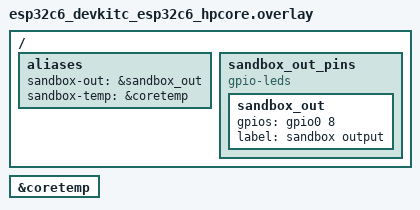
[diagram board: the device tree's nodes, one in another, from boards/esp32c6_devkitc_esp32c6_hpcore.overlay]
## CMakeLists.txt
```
# SPDX-License-Identifier: Apache-2.0

cmake_minimum_required(VERSION 3.20.0)
find_package(Zephyr REQUIRED HINTS $ENV{ZEPHYR_BASE})
project(behavior_sandbox)

zephyr_syscall_header(${CMAKE_CURRENT_SOURCE_DIR}/src/cap_surface.h)

target_sources(app PRIVATE
  src/main.c
  src/cap_surface.c
  src/policy.c
)
```

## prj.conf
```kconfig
CONFIG_USERSPACE=y
CONFIG_APPLICATION_DEFINED_SYSCALL=y

CONFIG_GPIO=y
CONFIG_SENSOR=y

CONFIG_TASK_WDT=y
CONFIG_TASK_WDT_CHANNELS=4

CONFIG_LOG=y
CONFIG_LOG_MODE_MINIMAL=y

CONFIG_THREAD_NAME=y
CONFIG_THREAD_STACK_INFO=y

# Containment demo deliberately triggers a fault; keep running afterwards.
CONFIG_TEST_RANDOM_GENERATOR=n
```

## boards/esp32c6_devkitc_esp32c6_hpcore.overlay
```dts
/*
 * Copyright (c) 2026 Espressif Systems (Shanghai) Co., Ltd.
 *
 * SPDX-License-Identifier: Apache-2.0
 */

/ {
	aliases {
		sandbox-out = &sandbox_out;
		sandbox-temp = &coretemp;
	};

	sandbox_out_pins {
		compatible = "gpio-leds";

		sandbox_out: sandbox_out {
			gpios = <&gpio0 8 GPIO_ACTIVE_HIGH>;
			label = "sandbox output";
		};
	};
};

&coretemp {
	status = "okay";
};
```

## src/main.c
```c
/*
 * Copyright (c) 2026 Espressif Systems (Shanghai) Co., Ltd.
 *
 * SPDX-License-Identifier: Apache-2.0
 */

#include "cap_surface.h"
#include "policy.h"

#include <zephyr/kernel.h>
#include <zephyr/sys/printk.h>
#include <zephyr/logging/log.h>
#include <zephyr/fatal.h>
#include <zephyr/task_wdt/task_wdt.h>
#include <zephyr/app_memory/app_memdomain.h>

LOG_MODULE_REGISTER(behavior_sandbox, CONFIG_LOG_DEFAULT_LEVEL);

extern int cap_surface_init(void);

/*
 * Contain faults to the offending thread instead of halting the system. When
 * this handler returns, the kernel aborts the faulting thread and continues,
 * so a misbehaving sandbox cannot take down the supervisor or other sandboxes.
 * Kernel panics are not recoverable and must still halt.
 */
void k_sys_fatal_error_handler(unsigned int reason, const struct arch_esf *esf)
{
	ARG_UNUSED(esf);

	if (reason == K_ERR_KERNEL_PANIC) {
		printk("supervisor: kernel panic, halting\n");
		k_fatal_halt(reason);
	}

	printk("supervisor: contained fault (reason %u) in thread %p, killing it\n",
	       reason, k_current_get());
}

#define SANDBOX_STACK_SIZE 2048
#define SANDBOX_PRIO       5
#define WDT_TIMEOUT_MS     1500

K_THREAD_STACK_DEFINE(sandbox_stack, SANDBOX_STACK_SIZE);
static struct k_thread sandbox_thread;

/* Private heap the sandbox is routed to; a future quota primitive caps this. */
K_HEAP_DEFINE(sandbox_heap, 1024);

/* Memory domain that isolates the sandbox from the rest of the system. */
static struct k_mem_domain sandbox_domain;

static volatile bool wdt_fired;
static int wdt_chan;

/* Signaled by the watchdog ISR callback; the supervisor thread does the abort. */
static K_SEM_DEFINE(wdt_kill_sem, 0, 1);

static void wdt_callback(int channel_id, void *user_data)
{
	ARG_UNUSED(channel_id);
	ARG_UNUSED(user_data);

	/*
	 * Runs in the system-clock ISR context. k_thread_abort() of another
	 * thread is not safe here, so only signal the supervisor thread, which
	 * performs the abort in thread context.
	 */
	wdt_fired = true;
	k_sem_give(&wdt_kill_sem);
}

static void wait_for_wdt_kill(k_tid_t tid)
{
	/*
	 * The watchdog tracks the sandbox's liveness. A runaway sandbox never
	 * yields a liveness signal, so the supervisor does not feed the channel.
	 * When the timeout fires, the ISR callback signals us and we abort the
	 * thread here, in thread context, then join the now-dead thread.
	 */
	k_sem_take(&wdt_kill_sem, K_FOREVER);
	printk("supervisor: watchdog fired, aborting runaway sandbox\n");
	k_thread_abort(tid);
	k_thread_join(tid, K_FOREVER);
}

static void run_demo(const char *name, enum policy_kind kind, bool guarded)
{
	printk("\n=== demo: %s ===\n", name);
	wdt_fired = false;

	k_tid_t tid = k_thread_create(&sandbox_thread, sandbox_stack,
				      SANDBOX_STACK_SIZE, policy_run,
				      (void *)(uintptr_t)kind, NULL, NULL,
				      SANDBOX_PRIO, K_USER | K_INHERIT_PERMS,
				      K_FOREVER);

	k_thread_heap_assign(&sandbox_thread, &sandbox_heap);

	if (k_mem_domain_add_thread(&sandbox_domain, tid) != 0) {
		printk("supervisor: failed to place thread in mem domain\n");
	}

	if (guarded) {
		wdt_chan = task_wdt_add(WDT_TIMEOUT_MS, wdt_callback, &sandbox_thread);
	}

	k_thread_start(tid);

	if (guarded) {
		wait_for_wdt_kill(tid);
		task_wdt_delete(wdt_chan);
	} else {
		k_thread_join(tid, K_FOREVER);
	}

	printk("supervisor: sandbox for '%s' is gone, system still alive\n", name);
}

int main(void)
{
	printk("\nbehavior sandbox PoC on %s\n", CONFIG_BOARD);

	if (cap_surface_init() != 0) {
		printk("supervisor: capability surface init failed\n");
		return 0;
	}

	if (task_wdt_init(NULL) != 0) {
		printk("supervisor: task_wdt_init failed\n");
		return 0;
	}

	k_mem_domain_init(&sandbox_domain, 0, NULL);

	run_demo("happy path (capabilities only)", POLICY_GOOD, false);
	run_demo("containment (raw access traps)", POLICY_ROGUE, false);
	run_demo("supervision (runaway killed)", POLICY_RUNAWAY, true);

	printk("\nall demos complete: supervisor survived every sandbox\n");
	return 0;
}
```

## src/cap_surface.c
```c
/*
 * Copyright (c) 2026 Espressif Systems (Shanghai) Co., Ltd.
 *
 * SPDX-License-Identifier: Apache-2.0
 */

#include "cap_surface.h"

#include <zephyr/kernel.h>
#include <zephyr/device.h>
#include <zephyr/drivers/gpio.h>
#include <zephyr/drivers/sensor.h>
#include <zephyr/logging/log.h>
#include <zephyr/internal/syscall_handler.h>

LOG_MODULE_DECLARE(behavior_sandbox, CONFIG_LOG_DEFAULT_LEVEL);

/*
 * Controllable output pin: a free GPIO the sandbox is permitted to toggle.
 * Wire an LED/scope here to observe the happy-path capability call.
 */
static const struct gpio_dt_spec out_pin =
	GPIO_DT_SPEC_GET(DT_ALIAS(sandbox_out), gpios);

static const struct device *const die_temp =
	DEVICE_DT_GET(DT_ALIAS(sandbox_temp));

int cap_surface_init(void)
{
	int ret;

	if (!gpio_is_ready_dt(&out_pin)) {
		LOG_ERR("sandbox output pin not ready");
		return -ENODEV;
	}

	ret = gpio_pin_configure_dt(&out_pin, GPIO_OUTPUT_INACTIVE);
	if (ret < 0) {
		LOG_ERR("failed to configure output pin: %d", ret);
		return ret;
	}

	if (!device_is_ready(die_temp)) {
		LOG_ERR("die temperature sensor not ready");
		return -ENODEV;
	}

	return 0;
}

int z_impl_cap_led_set(bool on)
{
	return gpio_pin_set_dt(&out_pin, on ? 1 : 0);
}

int z_impl_cap_sensor_read(int32_t *milli_c)
{
	struct sensor_value val;
	int ret;

	ret = sensor_sample_fetch(die_temp);
	if (ret < 0) {
		return ret;
	}

	ret = sensor_channel_get(die_temp, SENSOR_CHAN_DIE_TEMP, &val);
	if (ret < 0) {
		return ret;
	}

	*milli_c = val.val1 * 1000 + val.val2 / 1000;
	return 0;
}

void z_impl_cap_sleep(uint32_t ms)
{
	k_msleep((int32_t)ms);
}

#ifdef CONFIG_USERSPACE

static inline int z_vrfy_cap_led_set(bool on)
{
	return z_impl_cap_led_set(on);
}
#include <zephyr/syscalls/cap_led_set_mrsh.c>

static inline int z_vrfy_cap_sensor_read(int32_t *milli_c)
{
	K_OOPS(K_SYSCALL_MEMORY_WRITE(milli_c, sizeof(*milli_c)));
	return z_impl_cap_sensor_read(milli_c);
}
#include <zephyr/syscalls/cap_sensor_read_mrsh.c>

static inline void z_vrfy_cap_sleep(uint32_t ms)
{
	z_impl_cap_sleep(ms);
}
#include <zephyr/syscalls/cap_sleep_mrsh.c>

#endif /* CONFIG_USERSPACE */
```

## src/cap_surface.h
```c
/*
 * Copyright (c) 2026 Espressif Systems (Shanghai) Co., Ltd.
 *
 * SPDX-License-Identifier: Apache-2.0
 */

#ifndef BEHAVIOR_SANDBOX_CAP_SURFACE_H_
#define BEHAVIOR_SANDBOX_CAP_SURFACE_H_

#include <zephyr/kernel.h>
#include <stdint.h>
#include <stdbool.h>

/*
 * Capability surface: the only gate through which the sandboxed user-mode
 * behavior thread is allowed to touch hardware. Each capability is a real
 * Zephyr syscall, so a user thread that tries to reach hardware any other
 * way faults under PMP and is contained.
 */

/**
 * @brief Drive the controllable output pin.
 *
 * @param on true to assert the pin, false to deassert.
 * @return 0 on success, negative errno on failure.
 */
__syscall int cap_led_set(bool on);

/**
 * @brief Read the on-chip die temperature.
 *
 * @param milli_c Output, temperature in milli-degrees Celsius.
 * @return 0 on success, negative errno on failure.
 */
__syscall int cap_sensor_read(int32_t *milli_c);

/**
 * @brief Cooperative sleep available to the sandbox.
 *
 * @param ms Milliseconds to sleep.
 */
__syscall void cap_sleep(uint32_t ms);

#include <zephyr/syscalls/cap_surface.h>

#endif /* BEHAVIOR_SANDBOX_CAP_SURFACE_H_ */
```

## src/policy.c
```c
/*
 * Copyright (c) 2026 Espressif Systems (Shanghai) Co., Ltd.
 *
 * SPDX-License-Identifier: Apache-2.0
 */

#include "policy.h"
#include "cap_surface.h"

#include <zephyr/kernel.h>
#include <zephyr/logging/log.h>

LOG_MODULE_DECLARE(behavior_sandbox, CONFIG_LOG_DEFAULT_LEVEL);

static void policy_good(void)
{
	for (int i = 0; i < 5; i++) {
		int32_t milli_c = 0;
		int ret;

		(void)cap_led_set(true);
		cap_sleep(200);
		(void)cap_led_set(false);

		ret = cap_sensor_read(&milli_c);
		if (ret == 0) {
			LOG_INF("policy: die temp %d.%03d C",
				milli_c / 1000, milli_c % 1000);
		} else {
			LOG_WRN("policy: sensor read failed: %d", ret);
		}

		cap_sleep(800);
	}

	LOG_INF("policy: good behavior finished cleanly");
}

static void policy_rogue(void)
{
	/*
	 * The sandbox has no business touching arbitrary memory. This is the
	 * kind of thing a compromised or hallucinated payload would attempt.
	 * Under USERSPACE the PMP must trap this and abort only this thread,
	 * leaving the supervisor and the rest of the system alive.
	 */
	volatile uint32_t *forbidden = (volatile uint32_t *)0x60000000;

	LOG_WRN("policy: attempting raw access outside the capability gate");
	*forbidden = 0xdeadbeef;

	/* Must never be reached. */
	LOG_ERR("policy: containment FAILED, raw write succeeded");
}

static void policy_runaway(void)
{
	LOG_WRN("policy: entering runaway loop, watchdog must intervene");
	for (;;) {
		/* No capability calls, no yields: starve nothing but burn
		 * the watchdog budget so the supervisor must kill us.
		 */
	}
}

void policy_run(void *kind, void *unused1, void *unused2)
{
	ARG_UNUSED(unused1);
	ARG_UNUSED(unused2);

	switch ((enum policy_kind)(uintptr_t)kind) {
	case POLICY_GOOD:
		policy_good();
		break;
	case POLICY_ROGUE:
		policy_rogue();
		break;
	case POLICY_RUNAWAY:
		policy_runaway();
		break;
	default:
		LOG_ERR("policy: unknown kind");
		break;
	}
}
```

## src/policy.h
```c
/*
 * Copyright (c) 2026 Espressif Systems (Shanghai) Co., Ltd.
 *
 * SPDX-License-Identifier: Apache-2.0
 */

#ifndef BEHAVIOR_SANDBOX_POLICY_H_
#define BEHAVIOR_SANDBOX_POLICY_H_

/*
 * A behavior policy is the dynamic payload the sandbox executes. In a full
 * framework this is what an LLM would produce (as Wasm or a DSL); here it is
 * compiled C that runs in user mode and may only reach hardware through the
 * capability surface.
 */
enum policy_kind {
	/* Happy path: blink the pin and report die temperature. */
	POLICY_GOOD,
	/* Containment: attempt a raw access the cap-gate does not grant. */
	POLICY_ROGUE,
	/* Supervision: spin forever so the task watchdog must intervene. */
	POLICY_RUNAWAY,
};

/* Entry point executed inside the user-mode sandbox thread. */
void policy_run(void *kind, void *unused1, void *unused2);

#endif /* BEHAVIOR_SANDBOX_POLICY_H_ */
```
